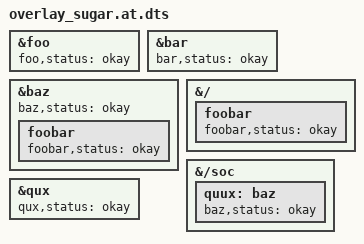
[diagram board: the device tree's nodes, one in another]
/dts-v1/;
/plugin/;

&foo {
	foo,status = "okay";
};

&bar {
	bar,status = "okay";
};

/ {
	fragment@0 {
		target = <&qux>;
		__overlay__ {
			qux,status = "okay";
		};
	};
};

&baz {
	baz,status = "okay";
	foobar: foobar {
		foobar,status = "okay";
	};
};

&{/} {
	foobar {
		foobar,status = "okay";
	};
};

&{/soc} {
	quux: baz {
		baz,status = "okay";
	};
};
